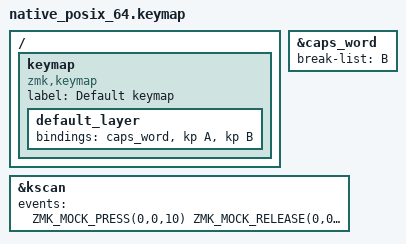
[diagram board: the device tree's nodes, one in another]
#include <dt-bindings/zmk/keys.h>
#include <behaviors.dtsi>
#include <dt-bindings/zmk/kscan_mock.h>

&caps_word {
	break-list = <B>;
};

/ {
	keymap {
		compatible = "zmk,keymap";
		label = "Default keymap";

		default_layer {
			bindings = <
				&caps_word &kp A
				&kp B
			>;
		};
	};
};


&kscan {
	events = <
	ZMK_MOCK_PRESS(0,0,10)
	ZMK_MOCK_RELEASE(0,0,10)
	ZMK_MOCK_PRESS(0,1,10)
	ZMK_MOCK_RELEASE(0,1,10)
	ZMK_MOCK_PRESS(1,0,10)
	ZMK_MOCK_RELEASE(1,0,10)
	ZMK_MOCK_PRESS(0,1,10)
	ZMK_MOCK_RELEASE(0,1,10)
	>;
};
